# samd21a_pack_usb_i2s register map
Registers are 8-bit, access not given, reset 0x0 unless marked. A register's access mark holds for its fields unless they carry their own. Offsets are from the block's base; lines under a group give offsets from that group; [hi:lo] are bit positions; {n}, {i} and the like mark numbered series; 'fields as' and 'values as' point back to an identical list; <NAME> marks a mode.

## Memory map
0x41005000 USB size 0x200 — Universal Serial Bus
0x42005000 I2S size 0x38 — Inter-IC Sound Interface

## Interrupts
7 USB — Universal Serial Bus
27 I2S — Inter-IC Sound Controller

## I2S — Inter-IC Sound Interface
Base 0x42005000
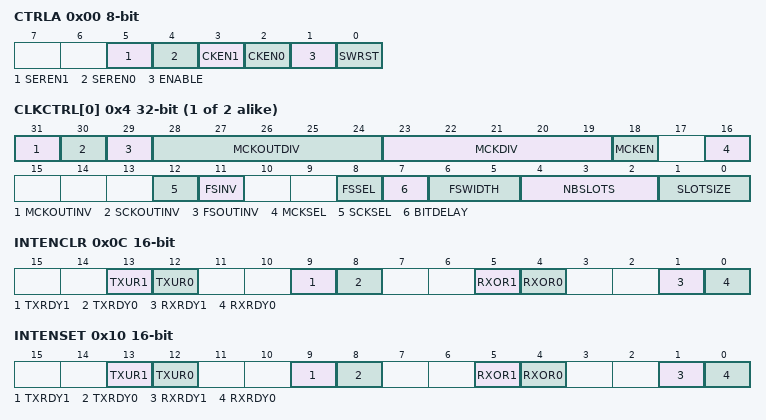
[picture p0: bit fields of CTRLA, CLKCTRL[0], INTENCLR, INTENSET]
0x00 CTRLA — Control A
  [5] SEREN1 — Serializer 1 Enable
  [4] SEREN0 — Serializer 0 Enable
  [3] CKEN1 — Clock Unit 1 Enable
  [2] CKEN0 — Clock Unit 0 Enable
  [1] ENABLE
  [0] SWRST — Software Reset
{0x4+4i} CLKCTRL[{i}] (i=0..1) 32-bit — Clock Unit n Control
  [31] MCKOUTINV — Master Clock Output Invert
  [30] SCKOUTINV — Serial Clock Output Invert
  [29] FSOUTINV — Frame Sync Output Invert
  [28:24] MCKOUTDIV — Master Clock Output Division Factor
  [23:19] MCKDIV — Master Clock Division Factor
  [18] MCKEN — Master Clock Enable
  [16] MCKSEL — Master Clock Select
    0=GCLK (GCLK_I2S_n is used as Master Clock n source); 1=MCKPIN (MCKn input pin is used as Master Clock n source)
  [12] SCKSEL — Serial Clock Select
    0=MCKDIV (Divided Master Clock n is used as Serial Clock n source); 1=SCKPIN (SCKn input pin is used as Serial Clock n source)
  [11] FSINV — Frame Sync Invert
  [8] FSSEL — Frame Sync Select
    0=SCKDIV (Divided Serial Clock n is used as Frame Sync n source); 1=FSPIN (FSn input pin is used as Frame Sync n source)
  [7] BITDELAY — Data Delay from Frame Sync
    0=LJ (Left Justified (0 Bit Delay)); 1=I2S (I2S (1 Bit Delay))
  [6:5] FSWIDTH — Frame Sync Width
    0=SLOT (Frame Sync Pulse is 1 Slot wide (default for I2S protocol)); 1=HALF (Frame Sync Pulse is half a Frame wide); 2=BIT (Frame Sync Pulse is 1 Bit wide); 3=BURST (Clock Unit n operates in Burst mode, with a 1-bit wide Frame Sync pulse per Data sample, only when Data transfer is requested)
  [4:2] NBSLOTS — Number of Slots in Frame
  [1:0] SLOTSIZE
    0=8-bit Slot for Clock Unit n; 1=16-bit Slot for Clock Unit n; 2=24-bit Slot for Clock Unit n; 3=32-bit Slot for Clock Unit n
0x0C INTENCLR 16-bit write-1-clears — Interrupt Enable Clear
  [13] TXUR1 — Transmit Underrun 1 Interrupt Enable
  [12] TXUR0 — Transmit Underrun 0 Interrupt Enable
  [9] TXRDY1 — Transmit Ready 1 Interrupt Enable
  [8] TXRDY0 — Transmit Ready 0 Interrupt Enable
  [5] RXOR1 — Receive Overrun 1 Interrupt Enable
  [4] RXOR0 — Receive Overrun 0 Interrupt Enable
  [1] RXRDY1 — Receive Ready 1 Interrupt Enable
  [0] RXRDY0 — Receive Ready 0 Interrupt Enable
0x10 INTENSET 16-bit write-1-sets — Interrupt Enable Set
  fields as INTENCLR
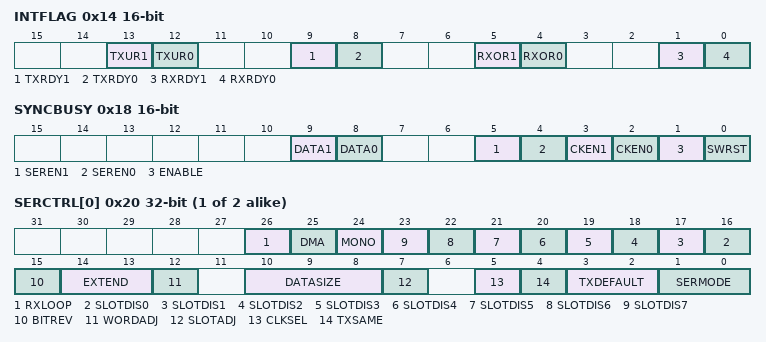
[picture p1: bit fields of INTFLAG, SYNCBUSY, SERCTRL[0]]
0x14 INTFLAG 16-bit write-1-clears — Interrupt Flag Status and Clear
  [13] TXUR1 — Transmit Underrun 1
  [12] TXUR0 — Transmit Underrun 0
  [9] TXRDY1 — Transmit Ready 1
  [8] TXRDY0 — Transmit Ready 0
  [5] RXOR1 — Receive Overrun 1
  [4] RXOR0 — Receive Overrun 0
  [1] RXRDY1 — Receive Ready 1
  [0] RXRDY0 — Receive Ready 0
0x18 SYNCBUSY 16-bit ro — Synchronization Status
  [9] DATA1 — Data 1 Synchronization Status
  [8] DATA0 — Data 0 Synchronization Status
  [5] SEREN1 — Serializer 1 Enable Synchronization Status
  [4] SEREN0 — Serializer 0 Enable Synchronization Status
  [3] CKEN1 — Clock Unit 1 Enable Synchronization Status
  [2] CKEN0 — Clock Unit 0 Enable Synchronization Status
  [1] ENABLE — Enable Synchronization Status
  [0] SWRST — Software Reset Synchronization Status
{0x20+4i} SERCTRL[{i}] (i=0..1) 32-bit — Serializer n Control
  [26] RXLOOP — Loop-back Test Mode
  [25] DMA — Single or Multiple DMA Channels
    0=SINGLE (Single DMA channel); 1=MULTIPLE (One DMA channel per data channel)
  [24] MONO — Mono Mode
    0=STEREO (Normal mode); 1=MONO (Left channel data is duplicated to right channel)
  [n+16] SLOTDIS{n} (n=0..7) — Slot {n} Disabled for this Serializer
  [15] BITREV — Data Formatting Bit Reverse
    0=MSBIT (Transfer Data Most Significant Bit (MSB) first (default for I2S protocol)); 1=LSBIT (Transfer Data Least Significant Bit (LSB) first)
  [14:13] EXTEND — Data Formatting Bit Extension
    0=ZERO (Extend with zeroes); 1=ONE (Extend with ones); 2=MSBIT (Extend with Most Significant Bit); 3=LSBIT (Extend with Least Significant Bit)
  [12] WORDADJ — Data Word Formatting Adjust
    0=RIGHT (Data is right adjusted in word); 1=LEFT (Data is left adjusted in word)
  [10:8] DATASIZE — Data Word Size
    0=32 bits; 1=24 bits; 2=20 bits; 3=18 bits; 4=16 bits; 5=16C (16 bits compact stereo); 6=8 bits; 7=8C (8 bits compact stereo)
  [7] SLOTADJ — Data Slot Formatting Adjust
    0=RIGHT (Data is right adjusted in slot); 1=LEFT (Data is left adjusted in slot)
  [5] CLKSEL — Clock Unit Selection
    0=CLK0 (Use Clock Unit 0); 1=CLK1 (Use Clock Unit 1)
  [4] TXSAME — Transmit Data when Underrun
    0=ZERO (Zero data transmitted in case of underrun); 1=SAME (Last data transmitted in case of underrun)
  [3:2] TXDEFAULT — Line Default Line when Slot Disabled
    0=ZERO (Output Default Value is 0); 1=ONE (Output Default Value is 1); 3=HIZ (Output Default Value is high impedance)
  [1:0] SERMODE — Serializer Mode
    0=RX (Receive); 1=TX (Transmit); 2=PDM2 (Receive one PDM data on each serial clock edge)
{0x30+4i} DATA[{i}] (i=0..1) 32-bit — Data n
  [31:0] DATA — Sample Data
